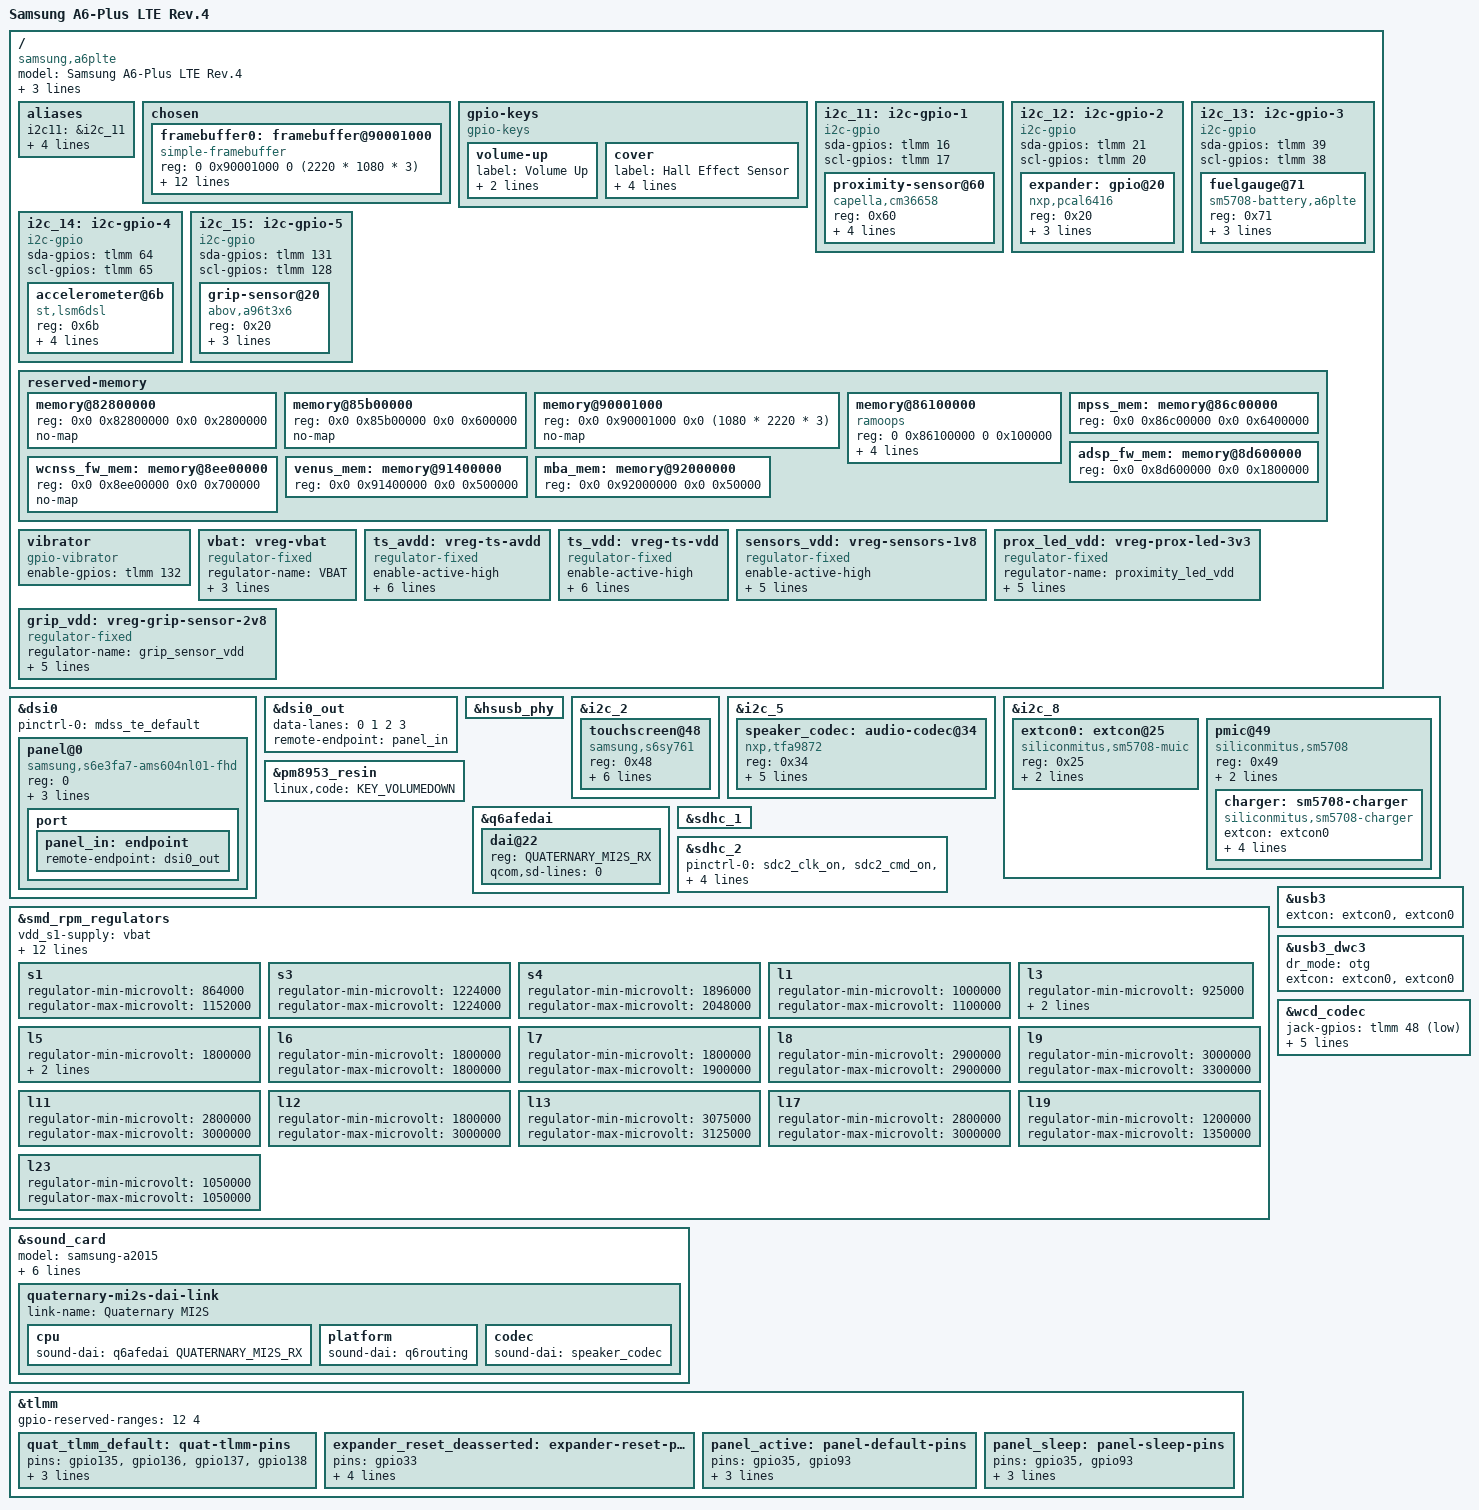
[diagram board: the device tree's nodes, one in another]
// SPDX-License-Identifier: BSD-3-Clause
// Copyright (c) 2022, The Linux Foundation. All rights reserved.

/dts-v1/;

#include "msm8953-pm8953.dtsi"

/ {
	model = "Samsung A6-Plus LTE Rev.4";
	compatible = "samsung,a6plte", "qcom,sdm450";
	chassis-type = "handset";
	qcom,msm-id = <338 0>;
	qcom,board-id = <8 4>;

	aliases {
		i2c11 = &i2c_11;
		i2c12 = &i2c_12;
		i2c13 = &i2c_13;
		i2c14 = &i2c_14;
		i2c15 = &i2c_15;
	};

	chosen {
		#address-cells = <2>;
		#size-cells = <2>;
		ranges;

		framebuffer0: framebuffer@90001000 {
			compatible = "simple-framebuffer";
			reg = <0 0x90001000 0 (2220 * 1080 * 3)>;

			width = <1080>;
			height = <2220>;
			stride = <(1080 * 3)>;
			format = "r8g8b8";

			power-domains = <&gcc MDSS_GDSC>;

			clocks = <&gcc GCC_MDSS_AHB_CLK>,
				 <&gcc GCC_MDSS_AXI_CLK>,
				 <&gcc GCC_MDSS_VSYNC_CLK>,
				 <&gcc GCC_MDSS_MDP_CLK>,
				 <&gcc GCC_MDSS_BYTE0_CLK>,
				 <&gcc GCC_MDSS_PCLK0_CLK>,
				 <&gcc GCC_MDSS_ESC0_CLK>;
		};
	};

	gpio-keys {
		compatible = "gpio-keys";

		volume-up {
			label = "Volume Up";
			gpios = <&tlmm 85 GPIO_ACTIVE_LOW>;
			linux,code = <KEY_VOLUMEUP>;
		};

		cover {
			label = "Hall Effect Sensor";
			gpios = <&tlmm 44 GPIO_ACTIVE_LOW>;
			linux,input-type = <EV_SW>;
			linux,code = <SW_LID>;
			linux,can-disable;
		};
	};

	i2c_11: i2c-gpio-1 {
		compatible = "i2c-gpio";
		sda-gpios = <&tlmm 16 (GPIO_ACTIVE_HIGH|GPIO_OPEN_DRAIN)>;
		scl-gpios = <&tlmm 17 (GPIO_ACTIVE_HIGH|GPIO_OPEN_DRAIN)>;

		#address-cells = <1>;
		#size-cells = <0>;
	};

	i2c_12: i2c-gpio-2 {
		compatible = "i2c-gpio";
		sda-gpios = <&tlmm 21 (GPIO_ACTIVE_HIGH|GPIO_OPEN_DRAIN)>;
		scl-gpios = <&tlmm 20 (GPIO_ACTIVE_HIGH|GPIO_OPEN_DRAIN)>;

		#address-cells = <1>;
		#size-cells = <0>;
	};

	i2c_13: i2c-gpio-3 {
		compatible = "i2c-gpio";
		sda-gpios = <&tlmm 39 (GPIO_ACTIVE_HIGH|GPIO_OPEN_DRAIN)>;
		scl-gpios = <&tlmm 38 (GPIO_ACTIVE_HIGH|GPIO_OPEN_DRAIN)>;

		#address-cells = <1>;
		#size-cells = <0>;
	};

	i2c_14: i2c-gpio-4 {
		compatible = "i2c-gpio";
		sda-gpios = <&tlmm 64 (GPIO_ACTIVE_HIGH|GPIO_OPEN_DRAIN)>;
		scl-gpios = <&tlmm 65 (GPIO_ACTIVE_HIGH|GPIO_OPEN_DRAIN)>;

		#address-cells = <1>;
		#size-cells = <0>;
	};

	i2c_15: i2c-gpio-5 {
		compatible = "i2c-gpio";
		sda-gpios = <&tlmm 131 (GPIO_ACTIVE_HIGH|GPIO_OPEN_DRAIN)>;
		scl-gpios = <&tlmm 128 (GPIO_ACTIVE_HIGH|GPIO_OPEN_DRAIN)>;

		#address-cells = <1>;
		#size-cells = <0>;
	};

	reserved-memory {
		memory@82800000 {
			reg = <0x0 0x82800000 0x0 0x2800000>;
			no-map;
		};

		memory@85b00000 {
			reg = <0x0 0x85b00000 0x0 0x600000>;
			no-map;
		};

		memory@90001000 {
			reg = <0x0 0x90001000 0x0 (1080 * 2220 * 3)>;
			no-map;
		};

		memory@86100000 {
			compatible = "ramoops";
			reg = <0 0x86100000 0 0x100000>;

			console-size = <0x40000>;
			ftrace-size = <0x40000>;
			pmsg-size = <0x40000>;
			record-size = <0x40000>;
		};

		mpss_mem: memory@86c00000 {
			reg = <0x0 0x86c00000 0x0 0x6400000>;
		};

		adsp_fw_mem: memory@8d600000  {
			reg = <0x0 0x8d600000 0x0 0x1800000>;
		};

		/delete-node/memory@8e700000;
		wcnss_fw_mem: memory@8ee00000 {
			reg = <0x0 0x8ee00000 0x0 0x700000>;
			no-map;
		};

		venus_mem: memory@91400000 {
			reg = <0x0 0x91400000 0x0 0x500000>;
		};

		mba_mem: memory@92000000 {
			reg = <0x0 0x92000000 0x0 0x50000>;
		};
	};

	vibrator {
		compatible = "gpio-vibrator";

		enable-gpios = <&tlmm 132 GPIO_ACTIVE_HIGH>;
	};

	vbat: vreg-vbat {
		compatible = "regulator-fixed";
		regulator-name = "VBAT";

		regulator-min-microvolt = <3700000>;
		regulator-max-microvolt = <3700000>;
		regulator-always-on;
	};

	ts_avdd: vreg-ts-avdd {
		compatible = "regulator-fixed";

		enable-active-high;
		gpio = <&tlmm 139 GPIO_ACTIVE_HIGH>;
		regulator-boot-on;
		regulator-max-microvolt = <3300000>;
		regulator-min-microvolt = <3300000>;
		regulator-name = "ts_avdd";
		vin-supply = <&vbat>;
	};

	ts_vdd: vreg-ts-vdd {
		compatible = "regulator-fixed";

		enable-active-high;
		gpio = <&tlmm 139 GPIO_ACTIVE_HIGH>;
		regulator-boot-on;
		regulator-max-microvolt = <1800000>;
		regulator-min-microvolt = <1800000>;
		regulator-name = "ts_vdd";
		vin-supply = <&pm8953_s4>;
	};

	sensors_vdd: vreg-sensors-1v8 {
		compatible = "regulator-fixed";

		enable-active-high;
		gpio = <&expander 6 GPIO_ACTIVE_HIGH>;
		regulator-max-microvolt = <1800000>;
		regulator-min-microvolt = <1800000>;
		regulator-name = "sensors_vdd";
		vin-supply = <&vbat>;
	};

	prox_led_vdd: vreg-prox-led-3v3 {
		compatible = "regulator-fixed";
		regulator-name = "proximity_led_vdd";
		regulator-min-microvolt = <3300000>;
		regulator-max-microvolt = <3300000>;
		startup-delay-us = <1000>;

		gpio = <&tlmm 127 GPIO_ACTIVE_HIGH>;

		enable-active-high;
	};

	grip_vdd: vreg-grip-sensor-2v8 {
		compatible = "regulator-fixed";
		regulator-name = "grip_sensor_vdd";
		regulator-min-microvolt = <2800000>;
		regulator-max-microvolt = <2800000>;
		startup-delay-us = <1000>;

		gpio = <&tlmm 87 GPIO_ACTIVE_HIGH>;

		enable-active-high;
	};

};

&dsi0 {
	pinctrl-names = "default";
	pinctrl-0 = <&mdss_te_default>;

	panel@0 {
		compatible = "samsung,s6e3fa7-ams604nl01-fhd";
		reg = <0>;

		pinctrl-names = "default", "sleep";
		pinctrl-0 = <&panel_active>;
		pinctrl-1 = <&panel_sleep>;

		reset-gpios = <&tlmm 50 GPIO_ACTIVE_LOW>;

		port {
			panel_in: endpoint {
				remote-endpoint = <&dsi0_out>;
			};
		};
	};
};

&dsi0_out {
	data-lanes = <0 1 2 3>;
	remote-endpoint = <&panel_in>;
};

&hsusb_phy {
	status = "okay";
};

&i2c_2 {
	status = "okay";

	touchscreen@48 {
		compatible = "samsung,s6sy761";
		reg = <0x48>;

		interrupt-parent = <&tlmm>;
		interrupts = <59 IRQ_TYPE_EDGE_FALLING>;

		avdd-supply = <&ts_avdd>;
		vdd-supply = <&ts_vdd>;

		touchscreen-size-x = <4096>;
		touchscreen-size-y = <4096>;
	};
};

&i2c_5 {
	status = "okay";

	speaker_codec: audio-codec@34 {
		compatible = "nxp,tfa9872";
		reg = <0x34>;

		max-coil-current = <12>;
		first-boost-voltage = <4>;
		first-boost-trip-lvl = <7>;
		second-boost-voltage = <5>;
		second-boost-trip-lvl = <5>;

		#sound-dai-cells = <0>;
		status = "okay";
	};
};

&i2c_8 {
	status = "okay";

	extcon0: extcon@25 {
		compatible = "siliconmitus,sm5708-muic";
		reg = <0x25>;

		interrupt-parent = <&tlmm>;
		interrupts = <63 IRQ_TYPE_LEVEL_HIGH>;
	};

	pmic@49 {
		compatible = "siliconmitus,sm5708";
		reg = <0x49>;

		interrupt-parent = <&tlmm>;
		interrupts = <60 IRQ_TYPE_EDGE_FALLING>;

		charger: sm5708-charger {
			compatible = "siliconmitus,sm5708-charger";

			extcon = <&extcon0>;

			enable-gpios = <&tlmm 34 GPIO_ACTIVE_HIGH>;

			charge-current = <1800>;
			float-voltage = <4100>;
			input-current = <1500>;
		};
	};
};

&i2c_11 {
	proximity-sensor@60 {
		compatible = "capella,cm36658";
		reg = <0x60>;

		interrupt-parent = <&tlmm>;
		interrupts = <43 IRQ_TYPE_EDGE_FALLING>;

		vdd-supply = <&sensors_vdd>;
		vled-supply = <&prox_led_vdd>;
	};
};

&i2c_12 {
	expander: gpio@20 {
		compatible = "nxp,pcal6416";
		reg = <0x20>;

		pinctrl-names = "default";
		pinctrl-0 = <&expander_reset_deasserted>;

		vcc-supply = <&pm8953_l5>;

		gpio-controller;
		#gpio-cells = <2>;
	};
};

&i2c_13 {
	fuelgauge@71 {
		compatible = "sm5708-battery,a6plte";
		reg = <0x71>;

		interrupt-parent = <&tlmm>;
		interrupts = <62 IRQ_TYPE_LEVEL_HIGH>;

		power-supplies = <&charger>;
	};
};

&i2c_14 {
	accelerometer@6b {
		compatible = "st,lsm6dsl";
		reg = <0x6b>;

		interrupt-parent = <&tlmm>;
		interrupts = <42 IRQ_TYPE_EDGE_RISING>;

		mount-matrix = "-1",  "0",  "0",
			        "0", "-1",  "0",
			        "0",  "0", "-1";

		vdd-supply = <&sensors_vdd>;
	};
};

&i2c_15 {
	grip-sensor@20 {
		compatible = "abov,a96t3x6";
		reg = <0x20>;

		interrupt-parent = <&tlmm>;
		interrupts = <86 IRQ_TYPE_EDGE_RISING>;

		vdd-supply = <&grip_vdd>;
	};
};

&pm8953_resin {
	status = "okay";
	linux,code = <KEY_VOLUMEDOWN>;
};

&q6afedai {
	dai@22 {
		reg = <QUATERNARY_MI2S_RX>;
		qcom,sd-lines = <0>;
	};
};

&sdhc_1 {
	status = "okay";
};

&sdhc_2 {
	status = "okay";

	pinctrl-names = "default", "sleep";
	pinctrl-0 = <&sdc2_clk_on &sdc2_cmd_on &sdc2_data_on &sdc2_cd_off>;
	pinctrl-1 = <&sdc2_clk_off &sdc2_cmd_off &sdc2_data_off &sdc2_cd_off>;

	cd-gpios = <&tlmm 133 GPIO_ACTIVE_LOW>;
};

&smd_rpm_regulators {
	vdd_s1-supply = <&vbat>;
	vdd_s2-supply = <&vbat>;
	vdd_s3-supply = <&vbat>;
	vdd_s4-supply = <&vbat>;
	vdd_s5-supply = <&vbat>;
	vdd_s6-supply = <&vbat>;
	vdd_s7-supply = <&vbat>;
	vdd_l1-supply = <&pm8953_s3>;
	vdd_l2_l3-supply = <&pm8953_s3>;
	vdd_l4_l5_l6_l7_l16_l19-supply = <&pm8953_s4>;
	vdd_l8_l11_l12_l13_l14_l15-supply = <&vbat>;
	vdd_l9_l10_l17_l18_l22-supply = <&vbat>;
	vdd_l23-supply = <&pm8953_s3>;

	s1 {
		regulator-min-microvolt = <864000>;
		regulator-max-microvolt = <1152000>;
	};

	s3 {
		regulator-min-microvolt = <1224000>;
		regulator-max-microvolt = <1224000>;
	};

	s4 {
		regulator-min-microvolt = <1896000>;
		regulator-max-microvolt = <2048000>;
	};

	l1 {
		regulator-min-microvolt = <1000000>;
		regulator-max-microvolt = <1100000>;
	};

	l3 {
		regulator-min-microvolt = <925000>;
		regulator-max-microvolt = <925000>;
		regulator-allow-set-load;
	};

	l5 {
		regulator-min-microvolt = <1800000>;
		regulator-max-microvolt = <1800000>;
		regulator-always-on;
	};

	l6 {
		regulator-min-microvolt = <1800000>;
		regulator-max-microvolt = <1800000>;
	};

	l7 {
		regulator-min-microvolt = <1800000>;
		regulator-max-microvolt = <1900000>;
	};

	l8 {
		regulator-min-microvolt = <2900000>;
		regulator-max-microvolt = <2900000>;
	};

	l9 {
		regulator-min-microvolt = <3000000>;
		regulator-max-microvolt = <3300000>;
	};

	l11 {
		regulator-min-microvolt = <2800000>;
		regulator-max-microvolt = <3000000>;
	};

	l12 {
		regulator-min-microvolt = <1800000>;
		regulator-max-microvolt = <3000000>;
	};

	l13 {
		regulator-min-microvolt = <3075000>;
		regulator-max-microvolt = <3125000>;
	};

	l17 {
		regulator-min-microvolt = <2800000>;
		regulator-max-microvolt = <3000000>;
	};

	l19 {
		regulator-min-microvolt = <1200000>;
		regulator-max-microvolt = <1350000>;
	};

	l23 {
		regulator-min-microvolt = <1050000>;
		regulator-max-microvolt = <1050000>;
	};
};

&sound_card {
	status = "okay";

	model = "samsung-a2015";

	pinctrl-names = "default", "sleep";
	pinctrl-0 = <&cdc_pdm_lines_act &cdc_pdm_lines_2_act &cdc_pdm_comp_lines_act &quat_tlmm_default>;
	pinctrl-1 = <&cdc_pdm_lines_sus &cdc_pdm_lines_2_sus &cdc_pdm_comp_lines_act &quat_tlmm_default>;

	quaternary-mi2s-dai-link {
		link-name = "Quaternary MI2S";
		cpu {
			sound-dai = <&q6afedai QUATERNARY_MI2S_RX>;
		};

		platform {
			sound-dai = <&q6routing>;
		};

		codec {
			sound-dai = <&speaker_codec>;
		};
	};
};

&tlmm {
	/* Fingerprint sensor at SPI4 (BLSP1 QUP4) */
	gpio-reserved-ranges = <12 4>;

	quat_tlmm_default: quat-tlmm-pins {
		pins = "gpio135", "gpio136", "gpio137", "gpio138";
		function = "sec_mi2s";
		drive-strength = <8>;
		bias-disable;
	};

	expander_reset_deasserted: expander-reset-pins {
		pins = "gpio33";
		function = "gpio";
		drive-strength = <2>;
		bias-disable;
		output-high;
	};

	panel_active: panel-default-pins {
		pins = "gpio35", "gpio93";
		function = "gpio";
		drive-strength = <8>;
		output-high;
	};

	panel_sleep: panel-sleep-pins {
		pins = "gpio35", "gpio93";
		function = "gpio";
		drive-strength = <2>;
		bias-disable;
	};
};

&usb3 {
	status = "okay";
	extcon = <&extcon0>, <&extcon0>;
};

&usb3_dwc3 {
	dr_mode = "otg";
	extcon = <&extcon0>, <&extcon0>;
};

&wcd_codec {
	jack-gpios = <&tlmm 48 GPIO_ACTIVE_LOW>;
	qcom,micbias-lvl = <2800>;
	qcom,micbias1-ext-cap;
	qcom,micbias2-ext-cap;
	qcom,mbhc-vthreshold-low = <150 237 450 500 600>;
	qcom,mbhc-vthreshold-high = <150 237 450 500 600>;
};
